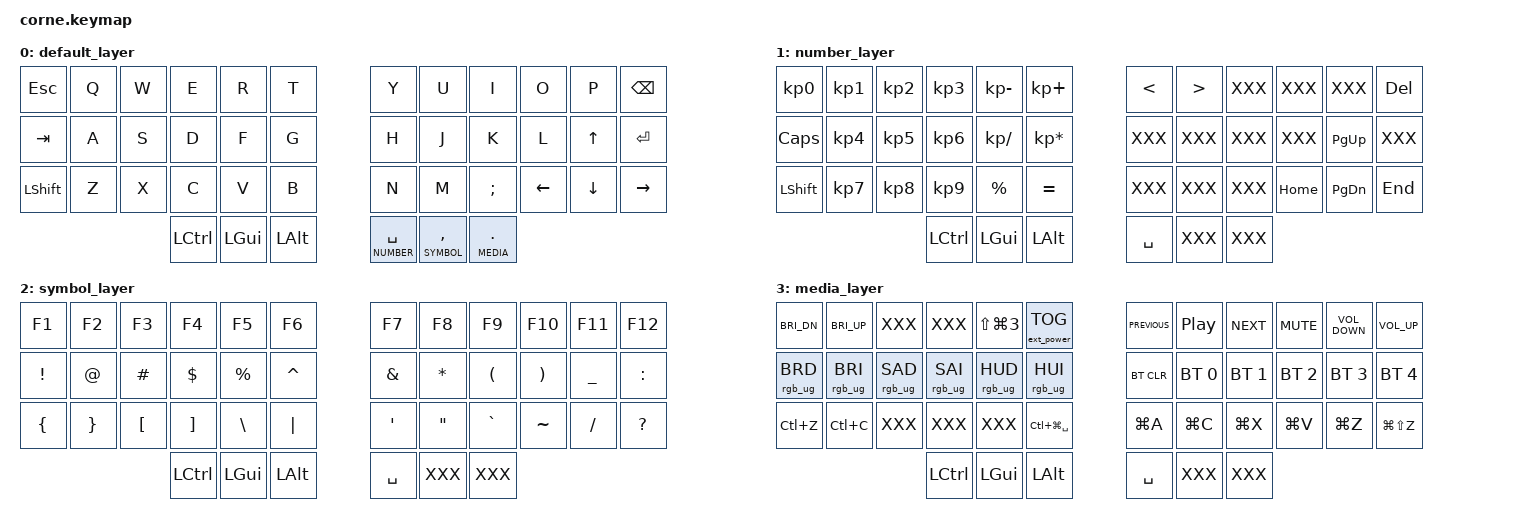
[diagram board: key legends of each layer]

// ### include {{{
#include <behaviors.dtsi>
#include <dt-bindings/zmk/keys.h>
#include <dt-bindings/zmk/bt.h>
#include <dt-bindings/zmk/outputs.h>
#include <dt-bindings/zmk/ext_power.h>
#include "keymap_german_mac_iso_zmk.h"
#include <dt-bindings/zmk/rgb.h>
// }}}
// ### ifdef CONFIG_ZMK_RGB_UNDERGLOW {{{
// #    include <dt-bindings/led/led.h>
// #    include <../boards/shields/corne/boards/nice_nano.overlay>
//#ifdef CONFIG_ZMK_RGB_UNDERGLOW
//#include <dt-bindings/zmk/rgb.h>
//#endif // CONFIG_ZMK_RGB_UNDERGLOW
//}}}
// ### define {{{
#define DEFAULT 0
#define NUMBER 1
#define SYMBOL 2
#define MEDIA 3
// combinadas para optimizar espacio
//#define MEDIA_ESC &lt MEDIA ESC
//#define MOUSE_TAB &lt MOUSE TAB
#define NUMBER_SPACE &lt NUMBER SPACE
#define SYMBOL_COMMA &lt SYMBOL COMMA
#define MEDIA_DOT &lt MEDIA DOT
// default_layer
#define LSHFT_COMMA &mt LSHFT COMMA
// function_layer
#define SPELL &kp LC(LG(D))
#define TRADUCT &kp LS(LA(T))
#define SNIPPET &kp LA(LG(G))
#define CLIPBRD &kp LA(LG(V))
#define EMOJI &kp LC(LG(SPACE))
#define TASKM &kp LC(LA(DEL)) // C-A-DEL
#define ZALL &kp LG(A)
#define ZCOPY &kp LG(C)
#define ZCUT &kp LG(X)
#define ZUNDO &kp LG(Z)
#define ZPASTE &kp LG(V)
#define ZREDO &kp LG(LS(Z))
#define ZSUSP &kp LC(Z)
#define ZKILL &kp LC(C)
// media_layer
#define SC_FLOW &kp LS(LG(NUMBER_1)) // <S-D-1> ScrenFlow app for MacOS
#define TXTSNIP &kp LS(LG(NUMBER_2)) // <S-D-2> TextSniper app for MacOS
#define SC_SHOT &kp LS(LG(NUMBER_3)) // <S-D-3> ScrenShot for all system see &kp PRINTSCREEN for MacOS
#define SC_SPSF &kp LS(LG(NUMBER_4)) // <S-D-4> Save picture of screen as a file for MacOS
#define SC_RE &kp LS(LG(NUMBER_5)) // <S-D-5> Screenshot and recording options for MacOS
#define OP_TERM &kp LC(LG(LA(SLASH))) // open terminal iTerm2 in current directory for MacOS
#define POS1 &kp LA(LG(NUMBER_1)) // positions of current app with carabiner integration for MacOS
#define POS2 &kp LA(LG(NUMBER_2)) // positions of current app with carabiner integration for MacOS
#define POS3 &kp LA(LG(NUMBER_3)) // positions of current app with carabiner integration for MacOS
#define POS4 &kp LA(LG(NUMBER_4)) // positions of current app with carabiner integration for MacOS
// define blueth
#define BT(n) BT_SEL n
//}}}
// ### macros {{{
#define MACRO(name, keys)           \
name: name##_macro {                \
	label = #name;                    \
	compatible = "zmk,behavior-macro";\
	#binding-cells = <0>;             \
	tap-ms = <1>;                     \
	wait-ms = <1>;                    \
	bindings = <keys>;                \
};

/ {
	macros {
		MACRO(example, &kp LS(H) &kp E &kp L &kp L &kp O)
		MACRO(mctechnology, &kp M &kp C &kp T &kp E &kp C &kp H &kp N &kp O &kp L &kp O &kp G &kp Y &kp N1 &kp N7)
		MACRO(linea, DE_END &kp LS(HOME) DE_BSPC)
	};
};
// }}}
// ### keymap {{{
/ {
   keymap {
      compatible = "zmk,keymap";
      // ### default_layer {{{
      default_layer {
         //    .------------------------------------------------.                         .-------------------------------------------------.
         //    | ESC |   Q   |   W   |   E   |   R   |   T      |                         |   Y   |   U   |   I   |   O   |   P   | BACKSPC |
         //    |--------+-------+-------+-------+-------+-------|                         |-------+-------+-------+-------+-------+---------|
         //    | TAB |   A   |   S   |   D   |   F   |   G      |                         |   H   |   J   |   K   |   L   |  UP   |   ENTER |
         //    |--------+-------+-------+-------+-------+-------|                         |-------+-------+-------+-------+-------+---------|
         //    |SHIFT|   Z   |   X   |   C   |   V   |   B      |                         |   N   |   M   |   ;   |  LEFT |  DOWN |   RIGHT |
         //    '---------------------------------------------------------|       |----------------------------------------------------------'
         //                             |  CTRL    |  CMD   |    ALT     |       | LT1 SPACE | LT2 ,     | LT3 .   |
         //                             '--------------------------------'       '----------------------------------'
         // label = "DEFAULT";
         bindings = <
            &kp ESC   &kp Q   &kp W   &kp E   &kp R      &kp T                            &kp Y        &kp U  &kp I         &kp O   &kp P     &kp BSPC
            &kp TAB   &kp A   &kp S   &kp D   &kp F      &kp G                            &kp H        &kp J  &kp K         &kp L     &kp UP    &kp RET
            &kp LSHFT  &kp Z   &kp X   &kp C   &kp V      &kp B                            &kp N       &kp M  &kp SEMI  &kp LEFT  &kp DOWN  &kp RIGHT
                                             &kp LCTRL  &kp LGUI  &kp LALT  NUMBER_SPACE  SYMBOL_COMMA  MEDIA_DOT
            >;
      };
      // }}}}
      // ### number_layer {{{
      number_layer {
         //   .-------------------------------------------------.                         .-------------------------------------------------.
         //   |   0     |   1   |   2   |   3   |   -   |   +   |                         |   <   |   >   |       |       |       | DELETE  |
         //   |---------+-------+-------+-------+-------+-------|                         |-------+-------+-------+-------+-------+---------|
         //   |CAPS_LOCK|   4   |   5   |   6   |   /   |   *   |                         |       |       |       |       |PAGE_UP|   	    |
         //   |---------+-------+-------+-------+-------+-------|                         |-------+-------+-------+-------+-------+---------|
         //   | SHIFT   |   7   |   8   |   9   |   %   |   =   |                         |       |       |       |  HOME |PAGE_DO|   END   |
         //   '----------------------------------------------------------|       |----------------------------------------------------------'
         //                             |  CTRL |  CMD  |      ALT       |       |      SPACE     |       |       |
         //                             '--------------------------------'       '--------------------------------'
         // label = "NUMBER";
         bindings = <
            &kp KP_N0  &kp KP_N1   &kp KP_N2  &kp KP_N3    &kp KP_MINUS   &kp KP_PLUS                     &kp LESS_THAN  &kp GREATER_THAN  XXX  XXX  XXX  &kp DEL
            &kp CAPS   &kp KP_N4   &kp KP_N5   &kp KP_N6    &kp KP_DIVIDE  &kp KP_MULTIPLY               XXX  XXX  XXX  XXX  &kp PG_UP  XXX
            &kp LSHFT  &kp KP_N7   &kp KP_N8   &kp KP_N9    &kp PRCNT   &kp EQUAL                    XXX  XXX  XXX  &kp HOME  &kp PG_DN  &kp END
                                            &kp LCTRL  &kp LGUI  &kp LALT                                 &kp SPACE  XXX  XXX
            >;
      };
      // }}}
      // ### symbol_layer {{{
      symbol_layer {
         //  .------------------------------------------------.          TODO:          .-------------------------------------------------.
         //  |   F1   |   F2  |   F3  |  F4   |  F5   |  F6   |                         |   F7  |  F8   |   F9  |  F10  |  F11  |   F12   |
         //  |--------+-------+-------+-------+-------+-------|                         |-------+-------+-------+-------+-------+---------|
         //  |   !    |   @   |   #   |   $   |   %   |   ^   |                         |   &   |   *   |   (   |    )  |   _   |    :    |
         //  |--------+-------+-------+-------+-------+-------|                         |-------+-------+-------+-------+-------+---------|
         //  |   {    |   }   |   [   |    ]  |   \   |   |   |                	        |   '   |   "   |   `   |    ~  |   /   |    ?    |
         //  '---------------------------------------------------------|       |----------------------------------------------------------'
         //                           |  CTRL |  CMD  |     ALT        |       |     SPACE      |       |       |
         //                           '--------------------------------'       '--------------------------------'
         // label = "SYMBOL";
         bindings = <
            &kp F1   &kp F2  &kp F3   &kp F4  &kp F5    &kp F6                    &kp F7  &kp F8  &kp F9  &kp F10  &kp F11   &kp F12
            &kp EXCL  &kp AT  &kp HASH   &kp DLLR &kp PRCNT   &kp CARET                    &kp AMPS  &kp STAR   &kp LPAR  &kp RPAR  &kp UNDER	&kp COLON
            &kp LBRC  &kp RBRC  &kp LBKT  &kp RBKT  &kp BSLH   &kp PIPE                     &kp SQT  &kp DQT  &kp GRAVE  &kp TILDE  &kp FSLH  &kp QMARK
                                                 &kp LCTRL  &kp LGUI  &kp LALT  &kp SPACE  XXX  XXX
            >;
      };
      // }}}
      // ### media_layer {{{
      media_layer {
         // .------------------------------------------------.                         .-------------------------------------------------.
         // | BRI_DN | BRI_UP|       |       |SC_SHOT|EP_TOG |                         |  PREV | PY/P  | NEXT  |  MUTE |VOL_DN |  VOL_UP |
         // |--------+-------+-------+-------+-------+-------|                         |-------+-------+-------+-------+-------+---------|
         // |RGBBRI- |RGBBRI+|RGBSAT-|RGBSAT+|RGBHUE-|RGBHUE+|                         |BT_CLR |  BT_0 |  BT_1 |  BT_2 |  BT_3 |  BT_4   |
         // |--------+-------+-------+-------+-------+-------|                         |-------+-------+-------+-------+-------+---------|
         // | CTRL-Z |CTRL-C |       |       | EMOJI |       |                         |  ALL  |  COPY |  CUT  | PASTE |  UNDO |   REDO  |       
         // '----------------------------------------------------------|       |----------------------------------------------------------'
         //                           |  CTRL |  CMD |       ALT       |       |       SPACE   |       |        |
         //                           '--------------------------------'       '--------------------------------'
         // LCTL(LGUI(KC_D)), LCTL(LGUI(KC_SPC))
         // label = "FUNCTION"; &rgb_ug RGB_BRD  &rgb_ug RGB_BRI  &rgb_ug RGB_SAD  &rgb_ug RGB_SAI  &rgb_ug RGB_HUD  &rgb_ug RGB_HUI
//&bt BT_CLR  &bt BT_SEL 0  &bt BT_SEL 1  &bt BT_SEL 2  &bt BT_SEL 3  &bt BT_SEL 4
         bindings = <
            			    &kp C_BRI_DN  &kp C_BRI_UP  XXX  XXX  SC_SHOT  &ext_power EP_TOG                    &kp C_PREVIOUS  &kp C_PLAY_PAUSE  &kp C_NEXT  &kp C_MUTE   &kp C_VOLUME_DOWN  &kp C_VOL_UP
&rgb_ug RGB_BRD  &rgb_ug RGB_BRI  &rgb_ug RGB_SAD  &rgb_ug RGB_SAI  &rgb_ug RGB_HUD  &rgb_ug RGB_HUI			&bt BT_CLR  &bt BT_SEL 0  &bt BT_SEL 1  &bt BT_SEL 2  &bt BT_SEL 3  &bt BT_SEL 4
            				     			      ZSUSP  ZKILL  XXX  XXX  XXX  EMOJI               	ZALL  ZCOPY  ZCUT  ZPASTE  ZUNDO  ZREDO  
                                                  			    &kp LCTRL &kp LGUI  &kp LALT       	&kp SPACE XXX   XXX
                                 >;
                         };
    	};
};
